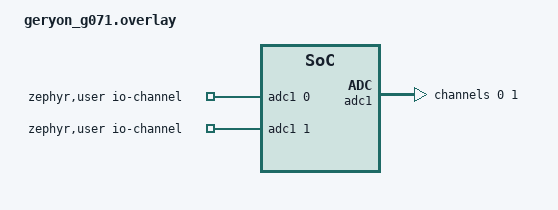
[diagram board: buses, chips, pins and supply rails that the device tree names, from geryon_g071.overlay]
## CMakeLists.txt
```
# SPDX-License-Identifier: Apache-2.0

cmake_minimum_required(VERSION 3.20.0)
set(BOARD_ROOT ${CMAKE_CURRENT_LIST_DIR})
find_package(Zephyr REQUIRED HINTS $ENV{ZEPHYR_BASE})

if(DEFINED ENV{VERSION})
project(app LANGUAGES C VERSION $ENV{VERSION})
else()
project(app LANGUAGES C VERSION 0.1.0)
endif()

set(PROJECT_VERSION_RC 7)

if(PROJECT_VERSION_RC)
  set(PROJECT_VERSION_SUFFIX "rc${PROJECT_VERSION_RC}")
else()
  set(PROJECT_VERSION_SUFFIX "")
endif()

if(PROJECT_VERSION_SUFFIX)
  set(PROJECT_VERSION ${PROJECT_VERSION}-${PROJECT_VERSION_SUFFIX})
endif()


configure_file(app_version.h.in ${CMAKE_BINARY_DIR}/app/include/app_version.h)

target_sources(app PRIVATE 
  src/main.c
  src/pwm.c  
  src/protocol.c
  src/io.c
  src/app_event_manager.c
  src/cset.c
  src/cmon.c
  src/mcp466.c
  src/pwm_gpio.c
  src/common.c
)
```

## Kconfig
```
menu "Geryon Application"

config SUPPORT_HAL_STM32
	bool "Enable HAL API for STM32"
	default y
	select USE_STM32_HAL_TIM
	select USE_STM32_HAL_TIM_EX
	select USE_STM32_HAL_GPIO
endmenu

menu "Zephyr Kernel"
source "$ZEPHYR_BASE/Kconfig.zephyr"
endmenu

module = GERYON_APP
module-str = Geryon App
source "${ZEPHYR_BASE}/subsys/logging/Kconfig.template.log_config"
```

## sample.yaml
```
sample:
  name: Geryon Lazer Application
```

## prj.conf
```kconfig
CONFIG_LOG=y
CONFIG_SHELL=y
# Config Random
CONFIG_ENTROPY_GENERATOR=y
CONFIG_TEST_RANDOM_GENERATOR=y

CONFIG_DAC=y
CONFIG_ADC=y
CONFIG_I2C=y
CONFIG_GPIO=y
CONFIG_GPIO_SHELL=y
CONFIG_LOG_DEFAULT_LEVEL=1
```

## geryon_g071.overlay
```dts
#include <zephyr/dt-bindings/adc/adc.h>

 / {
	zephyr,user {
		// io-channels = <&adc1 0>, <&adc1 1>, <&adc1 2>;
        io-channels = <&adc1 0>, <&adc1 1>;
	};
};

&adc1 {
    status = "okay";
	#address-cells = <1>;
	#size-cells = <0>;

	channel@0 {
		reg = <0>;
		zephyr,gain = "ADC_GAIN_1";
		zephyr,reference = "ADC_REF_INTERNAL";
		zephyr,acquisition-time = <ADC_ACQ_TIME_DEFAULT>;
		zephyr,resolution = <12>;
	};

    channel@1 {
		reg = <1>;
		zephyr,gain = "ADC_GAIN_1";
		zephyr,reference = "ADC_REF_INTERNAL";
		zephyr,acquisition-time = <ADC_ACQ_TIME_DEFAULT>;
		zephyr,resolution = <12>;
	};

    // channel@2 {
	// 	reg = <2>;
	// 	zephyr,gain = "ADC_GAIN_1";
	// 	zephyr,reference = "ADC_REF_INTERNAL";
	// 	zephyr,acquisition-time = <ADC_ACQ_TIME_DEFAULT>;
	// 	zephyr,resolution = <12>;
	// };
};
```

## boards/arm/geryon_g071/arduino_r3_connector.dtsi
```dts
/*
 * Copyright (c) 2019 Linaro Limited
 *
 * SPDX-License-Identifier: Apache-2.0
 */

 / {
	arduino_header: connector {
		compatible = "arduino-header-r3";
		#gpio-cells = <2>;
		gpio-map-mask = <0xffffffff 0xffffffc0>;
		gpio-map-pass-thru = <0 0x3f>;
		gpio-map = <0 0 &gpioa 0 0>,	/* A0 */
			   <1 0 &gpioa 1 0>,	/* A1 */
			   <2 0 &gpioa 4 0>,	/* A2 */
			   <3 0 &gpiob 1 0>,	/* A3 */
			   <4 0 &gpiob 11 0>,	/* A4 */
			   <5 0 &gpiob 12 0>,	/* A5 */
			   <6 0 &gpioc 5 0>,	/* D0 */
			   <7 0 &gpioc 4 0>,	/* D1 */
			   <8 0 &gpioa 10 0>,	/* D2 */
			   <9 0 &gpiob 3 0>,	/* D3 */
			   <10 0 &gpiob 5 0>,	/* D4 */
			   <11 0 &gpiob 4 0>,	/* D5 */
			   <12 0 &gpiob 14 0>,	/* D6 */
			   <13 0 &gpioa 8 0>,	/* D7 */
			   <14 0 &gpioa 9 0>,	/* D8 */
			   <15 0 &gpioc 7 0>,	/* D9 */
			   <16 0 &gpiob 0 0>,	/* D10 */
			   <17 0 &gpioa 7 0>,	/* D11 */
			   <18 0 &gpioa 6 0>,	/* D12 */
			   <19 0 &gpioa 5 0>,	/* D13 */
			   <20 0 &gpiob 9 0>,	/* D14 */
			   <21 0 &gpiob 8 0>;	/* D15 */
	};
};

arduino_i2c: &i2c1 {};
arduino_spi: &spi1 {};
arduino_serial: &usart1 {};
```

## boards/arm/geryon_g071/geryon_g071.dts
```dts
/*
 * Copyright (c) 2023 Marin Jurjević <marin.jurjevic@hotmail.com>
 *
 * SPDX-License-Identifier: Apache-2.0
 */

/dts-v1/;
#include <st/g0/stm32g071Xb.dtsi>
#include <st/g0/stm32g071r(6-8-b)tx-pinctrl.dtsi>
#include "arduino_r3_connector.dtsi"

/ {
	model = "STMicroelectronics STM32G071RB-NUCLEO board";
	compatible = "st,stm32g071rb-nucleo";

	chosen {
		zephyr,console = &usart1;
		zephyr,shell-uart = &usart1;
		zephyr,sram = &sram0;
		zephyr,flash = &flash0;
	};

	power-states {
		stop0: state0 {
			compatible = "zephyr,power-state";
			power-state-name = "suspend-to-idle";
			substate-id = <1>;
			min-residency-us = <20>;
		};
		stop1: state1 {
			compatible = "zephyr,power-state";
			power-state-name = "suspend-to-idle";
			substate-id = <2>;
			min-residency-us = <100>;
		};
	};

	board-control {
		global_en: global-en {
			compatible = "alma,input";
			control-gpios = <&gpioc 13 GPIO_ACTIVE_HIGH>;
			status = "okay";
		};
		status_out: status-out {
			compatible = "alma,output";
			control-gpios = <&gpioc 14 GPIO_ACTIVE_LOW>;
			status = "okay";
		};
		reset_int: reset-int {
			compatible = "alma,input";
			control-gpios = <&gpioc 15 GPIO_ACTIVE_HIGH>;
			status = "okay";
		};
		fan_out: fan-out {
			compatible = "alma,output";
			control-gpios = <&gpiof 0 GPIO_ACTIVE_HIGH>;
			status = "okay";
		};
		ot_int: ot-int {
			compatible = "alma,input";
			control-gpios = <&gpiof 1 GPIO_ACTIVE_HIGH>;
			status = "okay";
		};
		oc2_int: oc2-int {
			compatible = "alma,input";
			control-gpios = <&gpioa 6 GPIO_ACTIVE_HIGH>;
			status = "okay";
		};
		ov2_int: ov2-int {
			compatible = "alma,input";
			control-gpios = <&gpioa 7 GPIO_ACTIVE_HIGH>;
			status = "okay";
		};
		pulse2_out: pulse2-out {
			compatible = "alma,output";
			control-gpios = <&gpiob 1 GPIO_ACTIVE_HIGH>;
			status = "okay";
		};
		pwm2_out: pwm2-out {
			compatible = "alma,output";
			control-gpios = <&gpiob 2 GPIO_ACTIVE_HIGH>;
			status = "okay";
		};
		state2_out: state2-out {
			compatible = "alma,output";
			control-gpios = <&gpiob 11 GPIO_ACTIVE_HIGH>;
			status = "okay";
		};
		state3_out: state3-out {
			compatible = "alma,output";
			control-gpios = <&gpiob 12 GPIO_ACTIVE_HIGH>;
			status = "okay";
		};
		drv_en2_out: drv-en2-out {
			compatible = "alma,output";
			control-gpios = <&gpiob 15 GPIO_ACTIVE_HIGH>;
			status = "okay";
		};
		drv_en1_out: drv-en1-out {
			compatible = "alma,output";
			control-gpios = <&gpioa 8 GPIO_ACTIVE_HIGH>;
			status = "okay";
		};
		rs232_shdn_out: rs232-shdn-out {
			compatible = "alma,output";
			control-gpios = <&gpioc 6 GPIO_ACTIVE_HIGH>;
			status = "okay";
		};
		rs232_en_out: rs232-en-out {
			compatible = "alma,output";
			control-gpios = <&gpioc 7 GPIO_ACTIVE_HIGH>;
			status = "okay";
		};
		reset_n_out: reset-n-out {
			compatible = "alma,output";
			control-gpios = <&gpioa 11 GPIO_ACTIVE_HIGH>;
			status = "okay";
		};
		state1_out: state1-out {
			compatible = "alma,output";
			control-gpios = <&gpiod 0 GPIO_ACTIVE_HIGH>;
			status = "okay";
		};
		flt_int: flt-int {
			compatible = "alma,input";
			control-gpios = <&gpiob 8 GPIO_ACTIVE_HIGH>;
			status = "okay";
		};
		pulse1_out: pulse1-out {
			compatible = "alma,output";
			control-gpios = <&gpiod 3 GPIO_ACTIVE_HIGH>;
			status = "okay";
		};
		pwm1_out: pwm1-out {
			compatible = "alma,output";
			control-gpios = <&gpiod 2 GPIO_ACTIVE_HIGH>;
			status = "okay";
		};
		oc1_int: oc1-int {
			compatible = "alma,input";
			control-gpios = <&gpiob 5 GPIO_ACTIVE_HIGH>;
			status = "okay";
		};
		ov1_int: ov1-int {
			compatible = "alma,input";
			control-gpios = <&gpiob 4 GPIO_ACTIVE_HIGH>;
			status = "okay";
		};
	};

	aliases {
		alma-uart = &usart2;
		watchdog0 = &iwdg;
	};
};

&clk_lsi {
	status = "okay";
};

&clk_hsi {
	status = "okay";
};

&pll {
	div-m = <2>;
	mul-n = <25>;
	div-p = <2>;
	div-q = <2>;
	div-r = <4>;
	clocks = <&clk_hsi>;
	status = "okay";
};

&rcc {
	clocks = <&pll>;
	clock-frequency = <DT_FREQ_M(50)>;
	ahb-prescaler = <1>;
	apb1-prescaler = <1>;
};

&usart1 {
	pinctrl-0 = <&usart1_tx_pa9 &usart1_rx_pa10>;
	pinctrl-names = "default";
	current-speed = <115200>;
	status = "okay";
};

&usart2 {
	pinctrl-0 = <&usart2_tx_pa2 &usart2_rx_pa3>;
	pinctrl-names = "default";
	current-speed = <38400>;
	status = "okay";
};

&rtc {
	clocks = <&rcc STM32_CLOCK_BUS_APB1 0x00000400>,
	         <&rcc STM32_SRC_LSI RTC_SEL(2)>;
	status = "okay";
};

&iwdg {
	status = "okay";
};

&i2c1 {
	pinctrl-0 = <&i2c1_scl_pb6 &i2c1_sda_pb7>;
	pinctrl-names = "default";
	status = "okay";
	clock-frequency = <I2C_BITRATE_FAST>;
};

&adc1 {
	pinctrl-0 = <&adc1_in0_pa0 &adc1_in1_pa1>;
	pinctrl-names = "default";
	status = "okay";
	vref-mv = <3300>;
};

&dac1 {
	status = "okay";
	pinctrl-0 = <&dac1_out1_pa4 &dac1_out2_pa5>;
	pinctrl-names = "default";
};

&die_temp {
	status = "okay";
};

&flash0 {
	partitions {
		compatible = "fixed-partitions";
		#address-cells = <1>;
		#size-cells = <1>;

		/* Set 2KB of storage at the end of 128KB flash */
		storage_partition: partition@1f800 {
			label = "storage";
			reg = <0x0001f800 DT_SIZE_K(2)>;
		};
	};
};

&cpu0 {
	cpu-power-states = <&stop0 &stop1>;
};

&lptim1 {
	clocks = <&rcc STM32_CLOCK_BUS_APB1 0x80000000>,
	         <&rcc STM32_SRC_LSI LPTIM1_SEL(1)>;
	status = "okay";
};
```

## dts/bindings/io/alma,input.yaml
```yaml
description: Input IO

compatible: "alma,input"

include: base.yaml

properties:
    status:
      required: true

    control-gpios:
      type: phandle-array
      required: true
      description: |
        GPIO input
```

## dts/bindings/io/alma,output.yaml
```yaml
description: Alma Output IO

compatible: "alma,output"

include: base.yaml

properties:
    status:
      required: true

    control-gpios:
      type: phandle-array
      required: true
      description: |
        GPIO output
```

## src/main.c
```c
#include <zephyr/device.h>
#include <zephyr/kernel.h>
#include <zephyr/logging/log.h>
#include <zephyr/sys/printk.h>

LOG_MODULE_REGISTER(geryon_main, LOG_LEVEL_ERR);

#include "app_event_manager.h"
#include "cmon.h"
#include "cset.h"
#include "io.h"
#include "main.h"
#include "mcp466.h"
#include "protocol.h"
#include "pwm.h"
#include "pwm_gpio.h"

struct alma_data global_alma_data = {.sync_freq = 250000,
                                     .jitter = 1,
                                     .pulse_freq = 10,
                                     .pulse_dc = {10, 10},
                                     .op_mode = 1,
                                     .pulse_mode = 0};

#define MAX_NUM_GPIO_PINS 4

uint8_t pin_gpios[MAX_NUM_GPIO_PINS];
uint8_t freqs[MAX_NUM_GPIO_PINS];
uint8_t duty_cycles[MAX_NUM_GPIO_PINS];
uint8_t num_pins = 0;

void main_init_flow(void) {
  io_set(IO_STATUS_OUT, 0);
  io_set(IO_PULSE1_OUT, 1);
  io_set(IO_PULSE2_OUT, 0);
  io_set(IO_DRV_EN1_OUT, 1);
  io_set(IO_DRV_EN2_OUT, 0);
  io_set(IO_PWM1_OUT, 0);
  io_set(IO_PWM2_OUT, 0);
  cset_out(CSET_CH_1, 0);
  cset_out(CSET_CH_2, 0);
  mcp466_write(MCP466_CH_1, 0, 0);
  mcp466_write(MCP466_CH_2, 0, 0);
  mcp466_write(MCP466_CH_1, 1, 0);
  mcp466_write(MCP466_CH_2, 1, 0);
  io_set(IO_RS232_SHDN_OUT, 1);
  io_set(IO_RS232_EN_OUT, 0);
  io_set(IO_RESET_N_OUT, 1);
  io_set(IO_STATE1_OUT, 1);
  io_set(IO_STATE2_OUT, 0);
  io_set(IO_STATE3_OUT, 0);
}

void main_close_laser_flow(void) {
  pin_gpios[0] = IO_PWM1_OUT;
  pin_gpios[1] = IO_PWM2_OUT;
  pin_gpios[2] = CSET_CH_1;
  pin_gpios[3] = CSET_CH_2;
  num_pins = 4;
  stop_pwm_pins(pin_gpios, num_pins);
  io_set(IO_PWM1_OUT, 0);
  io_set(IO_PWM2_OUT, 0);
  cset_out(CSET_CH_1, 0);
  cset_out(CSET_CH_2, 0);
  io_set(IO_PULSE1_OUT, 0);
  io_set(IO_PULSE2_OUT, 0);
  io_set(IO_DRV_EN1_OUT, 0);
  io_set(IO_DRV_EN2_OUT, 0);
  io_set(IO_STATUS_OUT, 1);
}

void main_opmode_1_flow(void) {
  io_set(IO_PULSE1_OUT, 1);
  io_set(IO_PULSE2_OUT, 0);
  io_set(IO_DRV_EN1_OUT, 1);
  io_set(IO_DRV_EN2_OUT, 0);
  freqs[0] = global_alma_data.pulse_freq;
  duty_cycles[0] = global_alma_data.pulse_dc[0];
  num_pins = 1;
  if (global_alma_data.pulse_mode == 1) {
    io_set(IO_PWM1_OUT, 1);
    pin_gpios[0] = SIGNAL_CSET_1;
  } else if (global_alma_data.pulse_mode == 0) {
    cset_out(CSET_CH_1, 128);
    pin_gpios[0] = SIGNAL_PWM_1;
  }

  stop_pwm_pins(pin_gpios, num_pins);
  start_pwm_pins(pin_gpios, freqs, duty_cycles, num_pins, -1);
  io_set(IO_STATE1_OUT, 0);
  io_set(IO_STATE2_OUT, 0);
  io_set(IO_STATE3_OUT, 0);
}

void main_opmode_2_flow(void) {
  io_set(IO_PULSE1_OUT, 0);
  io_set(IO_PULSE2_OUT, 1);
  io_set(IO_DRV_EN1_OUT, 0);
  io_set(IO_DRV_EN2_OUT, 1);
  freqs[0] = global_alma_data.pulse_freq;
  duty_cycles[0] = global_alma_data.pulse_dc[1];
  num_pins = 1;
  if (global_alma_data.pulse_mode == 1) {
    io_set(IO_PWM2_OUT, 1);
    pin_gpios[0] = SIGNAL_CSET_2;
  } else if (global_alma_data.pulse_mode == 0) {
    cset_out(CSET_CH_2, 128);
    pin_gpios[0] = SIGNAL_PWM_2;
  }

  stop_pwm_pins(pin_gpios, num_pins);
  start_pwm_pins(pin_gpios, freqs, duty_cycles, num_pins, -1);
  io_set(IO_STATE1_OUT, 0);
  io_set(IO_STATE2_OUT, 0);
  io_set(IO_STATE3_OUT, 0);
}

void main_opmode_3_flow(void) {
  io_set(IO_PULSE1_OUT, 1);
  io_set(IO_PULSE2_OUT, 1);
  io_set(IO_DRV_EN1_OUT, 1);
  io_set(IO_DRV_EN2_OUT, 1);
  freqs[0] = global_alma_data.pulse_freq;
  freqs[1] = global_alma_data.pulse_freq;
  duty_cycles[0] = global_alma_data.pulse_dc[0];
  duty_cycles[1] = global_alma_data.pulse_dc[1];
  num_pins = 2;
  if (global_alma_data.pulse_mode == 1) {
    pin_gpios[0] = SIGNAL_CSET_1;
    pin_gpios[1] = SIGNAL_CSET_2;
    io_set(IO_PWM1_OUT, 1);
    io_set(IO_PWM2_OUT, 1);
  } else if (global_alma_data.pulse_mode == 0) {
    cset_out(CSET_CH_1, 128);
    cset_out(CSET_CH_2, 128);
    pin_gpios[0] = SIGNAL_PWM_1;
    pin_gpios[1] = SIGNAL_PWM_2;
  }

  stop_pwm_pins(pin_gpios, num_pins);
  start_pwm_pins(pin_gpios, freqs, duty_cycles, num_pins, -1);
  io_set(IO_STATE1_OUT, 0);
  io_set(IO_STATE2_OUT, 0);
  io_set(IO_STATE3_OUT, 1);
}

void main_opmode_4_flow(void) {
  io_set(IO_PULSE1_OUT, 1);
  io_set(IO_PULSE2_OUT, 1);
  io_set(IO_DRV_EN1_OUT, 1);
  io_set(IO_DRV_EN2_OUT, 1);
  freqs[0] = global_alma_data.pulse_freq;
  freqs[1] = global_alma_data.pulse_freq;
  duty_cycles[0] = global_alma_data.pulse_dc[0];
  duty_cycles[1] = global_alma_data.pulse_dc[1];
  if (global_alma_data.pulse_mode == 1) {
    pin_gpios[0] = SIGNAL_CSET_1;
    pin_gpios[1] = SIGNAL_CSET_2;
    io_set(IO_PWM1_OUT, 1);
    io_set(IO_PWM2_OUT, 1);
  } else if (global_alma_data.pulse_mode == 0) {
    cset_out(CSET_CH_1, 128);
    cset_out(CSET_CH_2, 128);
    pin_gpios[0] = SIGNAL_PWM_1;
    pin_gpios[1] = SIGNAL_PWM_2;
  }
  num_pins = 2;
  stop_pwm_pins(pin_gpios, num_pins);
  start_pwm_pins(pin_gpios, freqs, duty_cycles, num_pins, 1);
  io_set(IO_STATE1_OUT, 1);
  io_set(IO_STATE2_OUT, 1);
  io_set(IO_STATE3_OUT, 0);
}

void main(void) {
  io_init();
  io_interrupt_disable();
  cset_init();
  cmon_init();
  pwm_init();
  pwm_pins_init();
  mcp466_init();
  main_init_flow();
  protocol_init();
  while (1) {
    struct app_event evt;
    /* Wait for the next event */
    int err = app_event_manager_get(&evt);
    if (err) {
      LOG_WRN("Unable to get event. Err: %i", err);
      continue;
    }

    switch (evt.type) {
    case APP_EVENT_IN_GLOBAL_EN_RISING: {
      LOG_DBG("APP_EVENT_IN_GLOBAL_EN_RISING");
      /* Start pulse flow */
      pwm_start();
      io_set(IO_RS232_EN_OUT, 1); // Disable RS232
      if (global_alma_data.op_mode == 1)
        main_opmode_1_flow();
      else if (global_alma_data.op_mode == 2)
        main_opmode_2_flow();
      else if (global_alma_data.op_mode == 3)
        main_opmode_3_flow();
      else if (global_alma_data.op_mode == 4)
        main_opmode_4_flow();
      break;
    }
    case APP_EVENT_IN_GLOBAL_EN_FALLING: {
      LOG_DBG("APP_EVENT_IN_GLOBAL_EN_FALLING");
      /* Stop pusle flow */
      pwm_stop();
      num_pins = 4;
      pin_gpios[0] = SIGNAL_CSET_1;
      pin_gpios[1] = SIGNAL_CSET_2;
      pin_gpios[2] = SIGNAL_PWM_1;
      pin_gpios[3] = SIGNAL_PWM_2;
      stop_pwm_pins(pin_gpios, num_pins);
      io_set(IO_RS232_EN_OUT, 0); // Enable RS232
      break;
    }
    case APP_EVENT_IN_RESET: {
      LOG_DBG("APP_EVENT_IN_RESET");
      io_set(IO_RESET_N_OUT, 1);
      if (global_alma_data.op_mode == 1) {
        io_set(IO_PULSE1_OUT, 1);
        io_set(IO_PULSE2_OUT, 0);
        io_set(IO_DRV_EN1_OUT, 1);
        io_set(IO_DRV_EN2_OUT, 0);
        io_set(IO_STATE1_OUT, 0);
        io_set(IO_STATE2_OUT, 0);
      } else if (global_alma_data.op_mode == 2) {
        io_set(IO_PULSE1_OUT, 0);
        io_set(IO_PULSE2_OUT, 1);
        io_set(IO_DRV_EN1_OUT, 0);
        io_set(IO_DRV_EN2_OUT, 1);
        io_set(IO_STATE1_OUT, 0);
        io_set(IO_STATE2_OUT, 0);
      } else if (global_alma_data.op_mode == 3) {
        io_set(IO_PULSE1_OUT, 1);
        io_set(IO_PULSE2_OUT, 1);
        io_set(IO_DRV_EN1_OUT, 1);
        io_set(IO_DRV_EN2_OUT, 1);
        io_set(IO_STATE1_OUT, 0);
        io_set(IO_STATE2_OUT, 0);
        io_set(IO_STATE2_OUT, 1);
      } else if (global_alma_data.op_mode == 4) {
        io_set(IO_PULSE1_OUT, 1);
        io_set(IO_PULSE2_OUT, 1);
        io_set(IO_DRV_EN1_OUT, 1);
        io_set(IO_DRV_EN2_OUT, 1);
        io_set(IO_STATE1_OUT, 1);
        io_set(IO_STATE2_OUT, 1);
        io_set(IO_STATE2_OUT, 0);
      }
      break;
    }
    case APP_EVENT_IN_OT:
      LOG_DBG("APP_EVENT_IN_OT");
      main_close_laser_flow();
      protop_send_error_message(OT_ERR);
      break;
    case APP_EVENT_IN_OC2:
    LOG_DBG("APP_EVENT_IN_OC2");
      main_close_laser_flow();
      protop_send_error_message(OC2_ERR);
      break;
    case APP_EVENT_IN_OV2:
    LOG_DBG("APP_EVENT_IN_OV2");
      main_close_laser_flow();
      protop_send_error_message(OV2_ERR);
      break;
    case APP_EVENT_IN_FLT:
    LOG_DBG("APP_EVENT_IN_FLT");
      main_close_laser_flow();
      protop_send_error_message(FLT_ERR);
      break;
    case APP_EVENT_IN_OV1:
    LOG_DBG("APP_EVENT_IN_OV1");
      main_close_laser_flow();
      protop_send_error_message(OV1_ERR);
      break;
    case APP_EVENT_IN_OC1:
    LOG_DBG("APP_EVENT_IN_OC1");
      main_close_laser_flow();
      protop_send_error_message(OC1_ERR);
      break;
    default:
      break;
    }
  }
}
```

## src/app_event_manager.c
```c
#include <zephyr/kernel.h>
#include "app_event_manager.h"
#include <zephyr/logging/log.h>
LOG_MODULE_REGISTER(app_event_manager);

/* Define message queue */
K_MSGQ_DEFINE(app_event_msq, sizeof(struct app_event), APP_EVENT_QUEUE_SIZE, 4);

int app_event_manager_push(struct app_event *p_evt)
{
	return k_msgq_put(&app_event_msq, p_evt, K_NO_WAIT);
}

int app_event_manager_get(const struct app_event *p_evt)
{
	return k_msgq_get(&app_event_msq, (struct app_event *)p_evt, K_FOREVER);
}

char *app_event_type_to_string(enum app_event_type type)
{
	switch (type) {
		case APP_EVENT_IN_GLOBAL_EN_RISING:
			return "APP_EVENT_IN_GLOBAL_EN_RISING";
		case APP_EVENT_IN_GLOBAL_EN_FALLING:
			return "APP_EVENT_IN_GLOBAL_EN_FALLING";
		case APP_EVENT_IN_RESET:
			return "APP_EVENT_IN_RESET";
		case APP_EVENT_IN_OT:
			return "APP_EVENT_IN_OT";
		case APP_EVENT_IN_OC2:
			return "APP_EVENT_IN_OC2";
		case APP_EVENT_IN_OV2:
			return "APP_EVENT_IN_OV2";
		case APP_EVENT_IN_FLT:
			return "APP_EVENT_IN_FLT";
		case APP_EVENT_IN_OV1:
			return "APP_EVENT_IN_OV1";
		case APP_EVENT_IN_OC1:
			return "APP_EVENT_IN_OC1";
		default:
			return "UNKNOWN";
	}
}
```

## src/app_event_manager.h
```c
#ifndef _APP_EVENT_MANAGER_H
#define _APP_EVENT_MANAGER_H

/**
 * @brief Max size of event queue
 * 
 */
#define APP_EVENT_QUEUE_SIZE 24

/**
 * @brief Simplified macro for pushing an app event without data
 * 
 */
#define APP_EVENT_MANAGER_PUSH(x)                                                                  \
	struct app_event app_event_##x = {                                                         \
		.type = x,                                                                         \
	};                                                                                         \
	app_event_manager_push(&app_event_##x);

/**
 * @brief Used to interact with different functionality
 * in this application
 */
enum app_event_type {
	APP_EVENT_IN_GLOBAL_EN_RISING,
	APP_EVENT_IN_GLOBAL_EN_FALLING,
	APP_EVENT_IN_RESET,
	APP_EVENT_IN_OT,
	APP_EVENT_IN_OC2,
	APP_EVENT_IN_OV2,
	APP_EVENT_IN_FLT,
	APP_EVENT_IN_OV1,
	APP_EVENT_IN_OC1,
};

/**
 * @brief Application event that can be passed back to the main
 * context
 * 
 */
struct app_event {
	enum app_event_type type;
	union {
		int err;
	};
};

/**
 * @brief Get the string representation of the Application event
 * 
 * @param type app event type enum
 * @return char* NULL if error
 */
char *app_event_type_to_string(enum app_event_type type);

/**
 * @brief Pushes event to message queue
 * 
 * @param p_evt the event to be copied.
 * @return int 
 */
int app_event_manager_push(struct app_event *p_evt);

/**
 * @brief Gets an event from the message queue
 * 
 * @param p_evt pointer where the data will be copied to.
 * @return int 
 */
int app_event_manager_get(const struct app_event *p_evt);

#endif
```

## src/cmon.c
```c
#include <zephyr/kernel.h>
#include <zephyr/drivers/adc.h>
#include <zephyr/device.h>
#include <zephyr/devicetree.h>
#include <zephyr/kernel.h>
#include <zephyr/sys/printk.h>
#include <zephyr/sys/util.h>

#include <zephyr/logging/log.h>
LOG_MODULE_REGISTER(adc_alma, LOG_LEVEL_ERR);

#if !DT_NODE_EXISTS(DT_PATH(zephyr_user)) || \
	!DT_NODE_HAS_PROP(DT_PATH(zephyr_user), io_channels)
#error "No suitable devicetree overlay specified"
#endif

#define DT_SPEC_AND_COMMA(node_id, prop, idx) \
	ADC_DT_SPEC_GET_BY_IDX(node_id, idx),

/* Data of ADC io-channels specified in devicetree. */
static const struct adc_dt_spec adc_channels[] = {
	DT_FOREACH_PROP_ELEM(DT_PATH(zephyr_user), io_channels,
			     DT_SPEC_AND_COMMA)
};

static int16_t adc_buf;
struct adc_sequence sequence = {
	.buffer = &adc_buf,
	/* buffer size in bytes, not number of samples */
	.buffer_size = sizeof(adc_buf),
};


void cmon_init(void) {

	/* Configure channels individually prior to sampling. */
	for (size_t i = 0U; i < ARRAY_SIZE(adc_channels); i++) {
		if (!device_is_ready(adc_channels[i].dev)) {
			LOG_ERR("ADC controller device not ready");
			return;
		}

		int err = adc_channel_setup_dt(&adc_channels[i]);
		if (err < 0) {
			LOG_ERR("Could not setup channel #%d (%d)", i, err);
			return;
		}
	}

    LOG_INF("Setup ADC for CMON successfully");
}

int cmon_get(int channel) {
	int32_t val_mv;
	(void)adc_sequence_init_dt(&adc_channels[channel], &sequence);

	int err = adc_read(adc_channels[channel].dev, &sequence);
	if (err < 0) {
		LOG_ERR("Could not read (%d)", err);
        return 0;
	} else {
		LOG_DBG("Raw buf: %d", adc_buf);
	}

	/* conversion to mV may not be supported, skip if not */
	val_mv = adc_buf;
	err = adc_raw_to_millivolts_dt(&adc_channels[channel],
				       &val_mv);
	if (err < 0) {
		LOG_DBG(" (value in mV not available)");
	} else {
		LOG_INF(" Voltage: %d mV", val_mv);
	}

    return val_mv;
}
```

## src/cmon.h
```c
#ifndef CMON_H_
#define CMON_H_

#include <stdint.h>

enum {
    CMON_CH_1 = 0, 
    CMON_CH_2 = 1,
    E_SENSE = 2,
};

void cmon_init(void);
int cmon_get(int channel);

#endif /* CMON_H_ */
```

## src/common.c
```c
int custom_atoi(const char *str) {
    int result = 0;
    int sign = 1;
    int i = 0;

    while (str[i] == ' ' || str[i] == '\t')
        i++;

    if (str[i] == '-') {
        sign = -1;
        i++;
    } else if (str[i] == '+') {
        i++;
    }

    while (str[i] >= '0' && str[i] <= '9') {
        result = result * 10 + (str[i] - '0');
        i++;
    }

    return result * sign;
}
```

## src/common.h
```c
#ifndef MYCOMMON_H_
#define MYCOMMON_H_

int custom_atoi(const char *str);

#endif /* MYCOMMON_H_ */
```

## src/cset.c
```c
#include <zephyr/kernel.h>
#include <zephyr/drivers/dac.h>

#include <zephyr/logging/log.h>
LOG_MODULE_REGISTER(dac_alma, LOG_LEVEL_ERR);

#include "cset.h"

static const struct device *const dac_dev = DEVICE_DT_GET(DT_NODELABEL(dac1));

static int last_ch_value[2] = {0, 0};

static const struct dac_channel_cfg dac_ch_cfg[2] = {
    {
        .channel_id = 1,
        .resolution = 12,
    },
    {
        .channel_id = 2,
        .resolution = 12
    }
};

void cset_init(void) {
	if (!device_is_ready(dac_dev)) {
		LOG_ERR("DAC device %s is not ready", dac_dev->name);
		return;
	}

	for (int i = 0; i < CSET_NUM; i++) {
		int ret = dac_channel_setup(dac_dev, &dac_ch_cfg[i]);

		if (ret != 0) {
			LOG_ERR("Setting up of DAC channel failed with code %d", ret);
			return;
		}
	}

    LOG_INF("Setup DAC for CSET successfully");
}

void cset_out(int channel, int value) {
	if (!device_is_ready(dac_dev)) {
		LOG_ERR("DAC device %s is not ready", dac_dev->name);
		return;
	}

    last_ch_value[channel] = value;
	
    dac_write_value(dac_dev, dac_ch_cfg[channel].channel_id, value);
}

int  cset_get_last_value(int channel) {
    return last_ch_value[channel];
}
```

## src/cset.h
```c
#ifndef CSET_H_
#define CSET_H_

#include <stdint.h>

enum {
    CSET_CH_1,
    CSET_CH_2,
    CSET_NUM
};

void cset_init(void);
int  cset_get_last_value(int channel);
void cset_out(int channel, int value);

#endif /* CSET_H_ */
```

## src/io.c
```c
#include <zephyr/kernel.h>
#include <zephyr/drivers/gpio.h>
#include <zephyr/device.h>
#include <zephyr/sys/slist.h>
#include <zephyr/logging/log.h>
LOG_MODULE_REGISTER(io, LOG_LEVEL_ERR);

#include "io.h"
#include "app_event_manager.h"

static const struct gpio_dt_spec global_en_dt = GPIO_DT_SPEC_GET_OR(DT_NODELABEL(global_en), control_gpios, 0);
static const struct gpio_dt_spec status_out_dt = GPIO_DT_SPEC_GET_OR(DT_NODELABEL(status_out), control_gpios, 0);
static const struct gpio_dt_spec reset_int_dt = GPIO_DT_SPEC_GET_OR(DT_NODELABEL(reset_int), control_gpios, 0);
static const struct gpio_dt_spec fan_out_dt = GPIO_DT_SPEC_GET_OR(DT_NODELABEL(fan_out), control_gpios, 0);
static const struct gpio_dt_spec ot_int_dt = GPIO_DT_SPEC_GET_OR(DT_NODELABEL(ot_int), control_gpios, 0);
static const struct gpio_dt_spec oc2_int_dt = GPIO_DT_SPEC_GET_OR(DT_NODELABEL(oc2_int), control_gpios, 0);
static const struct gpio_dt_spec ov2_int_dt = GPIO_DT_SPEC_GET_OR(DT_NODELABEL(ov2_int), control_gpios, 0);
static const struct gpio_dt_spec pulse2_out_dt = GPIO_DT_SPEC_GET_OR(DT_NODELABEL(pulse2_out), control_gpios, 0);
static const struct gpio_dt_spec pwm2_out_dt = GPIO_DT_SPEC_GET_OR(DT_NODELABEL(pwm2_out), control_gpios, 0);
static const struct gpio_dt_spec state2_out_dt = GPIO_DT_SPEC_GET_OR(DT_NODELABEL(state2_out), control_gpios, 0);
static const struct gpio_dt_spec state3_out_dt = GPIO_DT_SPEC_GET_OR(DT_NODELABEL(state3_out), control_gpios, 0);
static const struct gpio_dt_spec drv_en2_out_dt = GPIO_DT_SPEC_GET_OR(DT_NODELABEL(drv_en2_out), control_gpios, 0);
static const struct gpio_dt_spec drv_en1_out_dt = GPIO_DT_SPEC_GET_OR(DT_NODELABEL(drv_en1_out), control_gpios, 0);
static const struct gpio_dt_spec rs232_shdn_out_dt = GPIO_DT_SPEC_GET_OR(DT_NODELABEL(rs232_shdn_out), control_gpios, 0);
static const struct gpio_dt_spec rs232_en_out_dt = GPIO_DT_SPEC_GET_OR(DT_NODELABEL(rs232_en_out), control_gpios, 0);
static const struct gpio_dt_spec reset_n_out_dt = GPIO_DT_SPEC_GET_OR(DT_NODELABEL(reset_n_out), control_gpios, 0);
static const struct gpio_dt_spec state1_out_dt = GPIO_DT_SPEC_GET_OR(DT_NODELABEL(state1_out), control_gpios, 0);
static const struct gpio_dt_spec flt_int_dt = GPIO_DT_SPEC_GET_OR(DT_NODELABEL(flt_int), control_gpios, 0);
static const struct gpio_dt_spec pulse1_out_dt = GPIO_DT_SPEC_GET_OR(DT_NODELABEL(pulse1_out), control_gpios, 0);
static const struct gpio_dt_spec pwm1_out_dt = GPIO_DT_SPEC_GET_OR(DT_NODELABEL(pwm1_out), control_gpios, 0);
static const struct gpio_dt_spec oc1_int_dt = GPIO_DT_SPEC_GET_OR(DT_NODELABEL(oc1_int), control_gpios, 0);
static const struct gpio_dt_spec ov1_int_dt = GPIO_DT_SPEC_GET_OR(DT_NODELABEL(ov1_int), control_gpios, 0);

static struct gpio_callback global_en_cb;
static struct gpio_callback reset_int_cb;
static struct gpio_callback ot_int_cb;
static struct gpio_callback oc2_int_cb;
static struct gpio_callback ov2_int_cb;
static struct gpio_callback flt_int_cb;
static struct gpio_callback oc1_int_cb;
static struct gpio_callback ov1_int_cb;

static void global_en_callback_handler(const struct device *port, struct gpio_callback *cb, gpio_port_pins_t pins) {
	struct app_event event;
	uint8_t level = gpio_pin_get_dt(&global_en_dt);
	LOG_DBG("Level %d", level);
	if (level == 0) {
		event.type = APP_EVENT_IN_GLOBAL_EN_FALLING;
	} else if (level == 1) {
		event.type = APP_EVENT_IN_GLOBAL_EN_RISING;
	} else {
		event.type = APP_EVENT_IN_GLOBAL_EN_FALLING;
	}
	app_event_manager_push(&event);
}

static void reset_int_callback_handler(const struct device *port, struct gpio_callback *cb, gpio_port_pins_t pins) {
	struct app_event event = {
		.type = APP_EVENT_IN_RESET,
	};
    app_event_manager_push(&event);
}

static void ot_int_callback_handler(const struct device *port, struct gpio_callback *cb, gpio_port_pins_t pins) {
	struct app_event event = {
		.type = APP_EVENT_IN_OT,
	};
    app_event_manager_push(&event);
}

static void oc2_int_callback_handler(const struct device *port, struct gpio_callback *cb, gpio_port_pins_t pins) {
	struct app_event event = {
		.type = APP_EVENT_IN_OC2,
	};
    app_event_manager_push(&event);
}

static void ov2_int_callback_handler(const struct device *port, struct gpio_callback *cb, gpio_port_pins_t pins) {
	struct app_event event = {
		.type = APP_EVENT_IN_OV2,
	};
    app_event_manager_push(&event);
}

static void flt_int_callback_handler(const struct device *port, struct gpio_callback *cb, gpio_port_pins_t pins) {
	struct app_event event = {
		.type = APP_EVENT_IN_FLT,
	};
    app_event_manager_push(&event);
}

static void oc1_int_callback_handler(const struct device *port, struct gpio_callback *cb, gpio_port_pins_t pins) {
	struct app_event event = {
		.type = APP_EVENT_IN_OV1,
	};
    app_event_manager_push(&event);
}

static void ov1_int_callback_handler(const struct device *port, struct gpio_callback *cb, gpio_port_pins_t pins) {
	struct app_event event = {
		.type = APP_EVENT_IN_OC1,
	};
    app_event_manager_push(&event);
}

int io_init(void)
{
	if (!device_is_ready(global_en_dt.port)) {
		LOG_ERR("Can't get the device %s", global_en_dt.port->name);
		return -EINVAL;
	}

	if (!device_is_ready(status_out_dt.port)) {
		LOG_ERR("Can't get the device %s", status_out_dt.port->name);
		return -EINVAL;
	}

	if (!device_is_ready(reset_int_dt.port)) {
		LOG_ERR("Can't get the device %s", reset_int_dt.port->name);
		return -EINVAL;
	}
    
	if (!device_is_ready(fan_out_dt.port)) {
		LOG_ERR("Can't get the device %s", fan_out_dt.port->name);
		return -EINVAL;
	}

	if (!device_is_ready(ot_int_dt.port)) {
		LOG_ERR("Can't get the device %s", ot_int_dt.port->name);
		return -EINVAL;
	}

	if (!device_is_ready(oc2_int_dt.port)) {
		LOG_ERR("Can't get the device %s", oc2_int_dt.port->name);
		return -EINVAL;
	}

	if (!device_is_ready(ov2_int_dt.port)) {
		LOG_ERR("Can't get the device %s", ov2_int_dt.port->name);
		return -EINVAL;
	}

	if (!device_is_ready(pulse2_out_dt.port)) {
		LOG_ERR("Can't get the device %s", pulse2_out_dt.port->name);
		return -EINVAL;
	}

	if (!device_is_ready(pwm2_out_dt.port)) {
		LOG_ERR("Can't get the device %s", pwm2_out_dt.port->name);
		return -EINVAL;
	}

	if (!device_is_ready(state2_out_dt.port)) {
		LOG_ERR("Can't get the device %s", state2_out_dt.port->name);
		return -EINVAL;
	}

	if (!device_is_ready(state3_out_dt.port)) {
		LOG_ERR("Can't get the device %s", state3_out_dt.port->name);
		return -EINVAL;
	}

	if (!device_is_ready(drv_en2_out_dt.port)) {
		LOG_ERR("Can't get the device %s", drv_en2_out_dt.port->name);
		return -EINVAL;
	}

	if (!device_is_ready(drv_en1_out_dt.port)) {
		LOG_ERR("Can't get the device %s", drv_en1_out_dt.port->name);
		return -EINVAL;
	}

	if (!device_is_ready(rs232_shdn_out_dt.port)) {
		LOG_ERR("Can't get the device %s", rs232_shdn_out_dt.port->name);
		return -EINVAL;
	}

	if (!device_is_ready(rs232_en_out_dt.port)) {
		LOG_ERR("Can't get the device %s", rs232_en_out_dt.port->name);
		return -EINVAL;
	}

	if (!device_is_ready(reset_n_out_dt.port)) {
		LOG_ERR("Can't get the device %s", reset_n_out_dt.port->name);
		return -EINVAL;
	}

	if (!device_is_ready(state1_out_dt.port)) {
		LOG_ERR("Can't get the device %s", state1_out_dt.port->name);
		return -EINVAL;
	}

	if (!device_is_ready(flt_int_dt.port)) {
		LOG_ERR("Can't get the device %s", flt_int_dt.port->name);
		return -EINVAL;
	}

	if (!device_is_ready(pulse1_out_dt.port)) {
		LOG_ERR("Can't get the device %s", pulse1_out_dt.port->name);
		return -EINVAL;
	}

	if (!device_is_ready(pwm1_out_dt.port)) {
		LOG_ERR("Can't get the device %s", pwm1_out_dt.port->name);
		return -EINVAL;
	}

	if (!device_is_ready(oc1_int_dt.port)) {
		LOG_ERR("Can't get the device %s", oc1_int_dt.port->name);
		return -EINVAL;
	}

	if (!device_is_ready(ov1_int_dt.port)) {
		LOG_ERR("Can't get the device %s", ov1_int_dt.port->name);
		return -EINVAL;
	}

    gpio_pin_configure_dt(&global_en_dt, GPIO_INPUT | GPIO_PULL_UP);
    gpio_pin_configure_dt(&status_out_dt, GPIO_OUTPUT);
    gpio_pin_configure_dt(&reset_int_dt, GPIO_INPUT);
    gpio_pin_configure_dt(&fan_out_dt, GPIO_OUTPUT);
    gpio_pin_configure_dt(&ot_int_dt, GPIO_INPUT);
    gpio_pin_configure_dt(&oc2_int_dt, GPIO_INPUT);
    gpio_pin_configure_dt(&ov2_int_dt, GPIO_INPUT);
    gpio_pin_configure_dt(&pulse2_out_dt, GPIO_OUTPUT);
    gpio_pin_configure_dt(&pwm2_out_dt, GPIO_OUTPUT);
    gpio_pin_configure_dt(&state2_out_dt, GPIO_OUTPUT);
    gpio_pin_configure_dt(&state3_out_dt, GPIO_OUTPUT);
    gpio_pin_configure_dt(&drv_en2_out_dt, GPIO_OUTPUT);
    gpio_pin_configure_dt(&drv_en1_out_dt, GPIO_OUTPUT);
    gpio_pin_configure_dt(&rs232_shdn_out_dt, GPIO_OUTPUT);
    gpio_pin_configure_dt(&rs232_en_out_dt, GPIO_OUTPUT);
    gpio_pin_configure_dt(&reset_n_out_dt, GPIO_OUTPUT);
    gpio_pin_configure_dt(&state1_out_dt, GPIO_OUTPUT);
    gpio_pin_configure_dt(&flt_int_dt, GPIO_INPUT);
    gpio_pin_configure_dt(&pulse1_out_dt, GPIO_OUTPUT);
    gpio_pin_configure_dt(&pwm1_out_dt, GPIO_OUTPUT);
    gpio_pin_configure_dt(&oc1_int_dt, GPIO_INPUT);
    gpio_pin_configure_dt(&ov1_int_dt, GPIO_INPUT);

    /* RS232 SHDN -> constant high by default */
    gpio_pin_set_dt(&rs232_shdn_out_dt, 1U);
    /* RS232 EN -> constant low by default */
    gpio_pin_set_dt(&rs232_en_out_dt, 0U);

    gpio_pin_interrupt_configure_dt(&global_en_dt, GPIO_INT_EDGE_BOTH);
	gpio_init_callback(&global_en_cb, global_en_callback_handler, BIT(global_en_dt.pin));
	gpio_add_callback(global_en_dt.port, &global_en_cb);

    gpio_pin_interrupt_configure_dt(&reset_int_dt, GPIO_INT_EDGE_RISING);
	gpio_init_callback(&reset_int_cb, reset_int_callback_handler, BIT(reset_int_dt.pin));
	gpio_add_callback(reset_int_dt.port, &reset_int_cb);

    gpio_pin_interrupt_configure_dt(&ot_int_dt, GPIO_INT_EDGE_RISING);
	gpio_init_callback(&ot_int_cb, ot_int_callback_handler, BIT(ot_int_dt.pin));
	gpio_add_callback(ot_int_dt.port, &ot_int_cb);

    gpio_pin_interrupt_configure_dt(&oc2_int_dt, GPIO_INT_EDGE_RISING);
	gpio_init_callback(&oc2_int_cb, oc2_int_callback_handler, BIT(oc2_int_dt.pin));
	gpio_add_callback(oc2_int_dt.port, &oc2_int_cb);

    gpio_pin_interrupt_configure_dt(&ov2_int_dt, GPIO_INT_EDGE_RISING);
	gpio_init_callback(&ov2_int_cb, ov2_int_callback_handler, BIT(ov2_int_dt.pin));
	gpio_add_callback(ov2_int_dt.port, &ov2_int_cb);

    gpio_pin_interrupt_configure_dt(&flt_int_dt, GPIO_INT_EDGE_RISING);
	gpio_init_callback(&flt_int_cb, flt_int_callback_handler, BIT(flt_int_dt.pin));
	gpio_add_callback(flt_int_dt.port, &flt_int_cb);

    gpio_pin_interrupt_configure_dt(&oc1_int_dt, GPIO_INT_EDGE_RISING);
	gpio_init_callback(&oc1_int_cb, oc1_int_callback_handler, BIT(oc1_int_dt.pin));
	gpio_add_callback(oc1_int_dt.port, &oc1_int_cb);

    gpio_pin_interrupt_configure_dt(&ov1_int_dt, GPIO_INT_EDGE_RISING);
	gpio_init_callback(&ov1_int_cb, ov1_int_callback_handler, BIT(ov1_int_dt.pin));
	gpio_add_callback(ov1_int_dt.port, &ov1_int_cb);

	LOG_DBG("Initialized the IO Interface successfully");
	return 0;
}

void io_set(int id, int level) {
	switch (id) {
	case IO_STATUS_OUT:
		gpio_pin_set_dt(&status_out_dt, level);
		break;
	case IO_FAN_OUT:
		gpio_pin_set_dt(&fan_out_dt, level);
		break;
	case IO_PULSE2_OUT:
		gpio_pin_set_dt(&pulse2_out_dt, level);
		break;
	case IO_PWM2_OUT:
		gpio_pin_set_dt(&pwm2_out_dt, level);
		break;
	case IO_STATE2_OUT:
		gpio_pin_set_dt(&state2_out_dt, level);
		break;
	case IO_STATE3_OUT:
		gpio_pin_set_dt(&state3_out_dt, level);
		break;
	case IO_DRV_EN2_OUT:
		gpio_pin_set_dt(&drv_en2_out_dt, level);
		break;
	case IO_DRV_EN1_OUT:
		gpio_pin_set_dt(&drv_en1_out_dt, level);
		break;
	case IO_RS232_SHDN_OUT:
		gpio_pin_set_dt(&rs232_shdn_out_dt, level);
		break;
	case IO_RESET_N_OUT:
		gpio_pin_set_dt(&reset_n_out_dt, level);
		break;
	case IO_RS232_EN_OUT:
		gpio_pin_set_dt(&rs232_en_out_dt, level);
		break;
	case IO_STATE1_OUT:
		gpio_pin_set_dt(&state1_out_dt, level);
		break;
	case IO_PULSE1_OUT:
		gpio_pin_set_dt(&pulse1_out_dt, level);
		break;
	case IO_PWM1_OUT:
		gpio_pin_set_dt(&pwm1_out_dt, level);
		break;
	default:
		break;
	}
}

int io_get(int id) {
	switch (id) {
		case IO_GLOBAL_EN:
			return gpio_pin_get_dt(&global_en_dt);
		case IO_STATUS_OUT:
			return gpio_pin_get_dt(&status_out_dt);
		case IO_RESET_INT:
			return gpio_pin_get_dt(&reset_int_dt);
		case IO_FAN_OUT:
			return gpio_pin_get_dt(&fan_out_dt);
		case IO_OT_INT:
			return gpio_pin_get_dt(&ot_int_dt);
		case IO_OC2_INT:
			return gpio_pin_get_dt(&oc2_int_dt);
		case IO_OV2_INT:
			return gpio_pin_get_dt(&ov2_int_dt);
		case IO_PULSE2_OUT:
			return gpio_pin_get_dt(&pulse2_out_dt);
		case IO_PWM2_OUT:
			return gpio_pin_get_dt(&pwm2_out_dt);
		case IO_STATE2_OUT:
			return gpio_pin_get_dt(&state2_out_dt);
		case IO_STATE3_OUT:
			return gpio_pin_get_dt(&state3_out_dt);
		case IO_DRV_EN2_OUT:
			return gpio_pin_get_dt(&drv_en2_out_dt);
		case IO_DRV_EN1_OUT:
			return gpio_pin_get_dt(&drv_en1_out_dt);
		case IO_RS232_SHDN_OUT:
			return gpio_pin_get_dt(&rs232_shdn_out_dt);
		case IO_RS232_EN_OUT:
			return gpio_pin_get_dt(&rs232_en_out_dt);
		case IO_RESET_N_OUT:
			return gpio_pin_get_dt(&reset_n_out_dt);
		case IO_STATE1_OUT:
			return gpio_pin_get_dt(&state1_out_dt);
		case IO_FLT_INT:
			return gpio_pin_get_dt(&flt_int_dt);
		case IO_PULSE1_OUT:
			return gpio_pin_get_dt(&pulse1_out_dt);
		case IO_PWM1_OUT:
			return gpio_pin_get_dt(&pwm1_out_dt);
		case IO_OC1_INT:
			return gpio_pin_get_dt(&oc1_int_dt);
		case IO_OV1_INT:
			return gpio_pin_get_dt(&ov1_int_dt);
	}
	return -EINVAL;
}

void io_interrupt_enable(void) {
    gpio_pin_interrupt_configure_dt(&reset_int_dt, GPIO_INT_EDGE_RISING);
	gpio_add_callback(reset_int_dt.port, &reset_int_cb);

    gpio_pin_interrupt_configure_dt(&ot_int_dt, GPIO_INT_EDGE_RISING);
	gpio_add_callback(ot_int_dt.port, &ot_int_cb);

    gpio_pin_interrupt_configure_dt(&oc2_int_dt, GPIO_INT_EDGE_RISING);
	gpio_add_callback(oc2_int_dt.port, &oc2_int_cb);

    gpio_pin_interrupt_configure_dt(&ov2_int_dt, GPIO_INT_EDGE_RISING);
	gpio_add_callback(ov2_int_dt.port, &ov2_int_cb);

    gpio_pin_interrupt_configure_dt(&flt_int_dt, GPIO_INT_EDGE_RISING);
	gpio_add_callback(flt_int_dt.port, &flt_int_cb);

    gpio_pin_interrupt_configure_dt(&oc1_int_dt, GPIO_INT_EDGE_RISING);
	gpio_add_callback(oc1_int_dt.port, &oc1_int_cb);

    gpio_pin_interrupt_configure_dt(&ov1_int_dt, GPIO_INT_EDGE_RISING);
	gpio_add_callback(ov1_int_dt.port, &ov1_int_cb);
}

void io_interrupt_disable(void) {
    gpio_pin_interrupt_configure_dt(&reset_int_dt, GPIO_INT_DISABLE);
	gpio_remove_callback(reset_int_dt.port, &reset_int_cb);

    gpio_pin_interrupt_configure_dt(&ot_int_dt, GPIO_INT_DISABLE);
	gpio_remove_callback(ot_int_dt.port, &ot_int_cb);

    gpio_pin_interrupt_configure_dt(&oc2_int_dt, GPIO_INT_DISABLE);
	gpio_remove_callback(oc2_int_dt.port, &oc2_int_cb);

    gpio_pin_interrupt_configure_dt(&ov2_int_dt, GPIO_INT_DISABLE);
	gpio_remove_callback(ov2_int_dt.port, &ov2_int_cb);

    gpio_pin_interrupt_configure_dt(&flt_int_dt, GPIO_INT_DISABLE);
	gpio_remove_callback(flt_int_dt.port, &flt_int_cb);

    gpio_pin_interrupt_configure_dt(&oc1_int_dt, GPIO_INT_DISABLE);
	gpio_remove_callback(oc1_int_dt.port, &oc1_int_cb);

    gpio_pin_interrupt_configure_dt(&ov1_int_dt, GPIO_INT_DISABLE);
	gpio_remove_callback(ov1_int_dt.port, &ov1_int_cb);
}
```

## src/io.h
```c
#ifndef IO_H_
#define IO_H_

#include <stdint.h>

enum {
    IO_GLOBAL_EN,
    IO_STATUS_OUT,
    IO_RESET_INT,
    IO_FAN_OUT,
    IO_OT_INT,
    IO_OC2_INT,
    IO_OV2_INT,
    IO_PULSE2_OUT,
    IO_PWM2_OUT,
    IO_STATE2_OUT,
    IO_STATE3_OUT,
    IO_DRV_EN2_OUT,
    IO_DRV_EN1_OUT,
    IO_RS232_SHDN_OUT,
    IO_RS232_EN_OUT,
    IO_RESET_N_OUT,
    IO_STATE1_OUT,
    IO_FLT_INT,
    IO_PULSE1_OUT,
    IO_PWM1_OUT,
    IO_OC1_INT,
    IO_OV1_INT,
};

int io_init(void);
void io_interrupt_enable(void);
void io_interrupt_disable(void);
void io_set(int id, int level);
int io_get(int id);

#endif /* IO_H_ */
```

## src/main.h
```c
#ifndef MAIN_H_
#define MAIN_H_

#include <stdint.h>

struct alma_data {
    uint32_t sync_freq;
    uint8_t jitter;
    uint32_t pulse_freq;
    uint8_t pulse_dc[2];
    uint8_t op_mode;
    uint8_t pulse_mode;
};

#endif /* MAIN_H_ */
```

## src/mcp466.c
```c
#include <zephyr/kernel.h>
#include <zephyr/drivers/i2c.h>

#include <zephyr/logging/log.h>
LOG_MODULE_REGISTER(mcp466_alma, LOG_LEVEL_DBG);

static const struct device *const mcp466_dev = DEVICE_DT_GET(DT_NODELABEL(i2c1));

void mcp466_init(void) {
    if (!device_is_ready(mcp466_dev)) {
		LOG_ERR("MCP466 device %s is not ready", mcp466_dev->name);
		return;
    }
}

void mcp466_write(int channel, uint8_t reg, uint16_t value) {
    if (!device_is_ready(mcp466_dev)) {
		LOG_ERR("MCP466 device %s is not ready", mcp466_dev->name);
		return;
    }

    uint8_t first_cmd_byte = 0x00;
    uint8_t second_cmd_byte = 0x00;
    uint16_t temp_data = value;
    uint8_t temp_byte = 0;
    // Prep the command bytes to write to the digital potentiometer
    reg *= 16;                // Shift the value of reg to the left by four bits
    first_cmd_byte |= reg;  // Load the register address into the first_cmd_byte
    temp_data &= 0x0100;            // Clear the top 7 bits and the lower byte of the input value to pick up the two data bits
    temp_data /= 256;               // Shift the top byte of the input value to the right by one byte
    temp_byte = (uint8_t)(temp_data);     // Store the top byte of the input value in a byte sized variable
    first_cmd_byte |= temp_byte;  // Load the two top input data bits into the first_cmd_byte
    temp_data = value;              // Load the input value into the temp_data
    temp_data &= 0x00FF;              // Clear the top byte
    second_cmd_byte = (uint8_t)(temp_data);  // Store the lower byte of the input value in the second_cmd_byte

    uint8_t tx_buf[2] = {first_cmd_byte, second_cmd_byte};
    i2c_write(mcp466_dev, tx_buf, sizeof(tx_buf), channel);
}

uint16_t mcp466_read(int channel, uint8_t reg) {
    if (!device_is_ready(mcp466_dev)) {
		LOG_ERR("MCP466 device %s is not ready", mcp466_dev->name);
		return 0;
    }

    uint8_t first_cmd_byte = 0x0C; // Prep the first_cmd_byte with 11b for reads
    // Prep the command bytes to read from the digital potentiometer
    reg *= 16; // Shift the value of Register to the left by four bits
    first_cmd_byte |= reg; // Load the register address into the first_cmd_byte

    uint8_t tx_buf[1] = {first_cmd_byte};
    uint8_t rx_buf[2] = {0x00};
    i2c_write_read(mcp466_dev, channel, tx_buf, sizeof(tx_buf), rx_buf, sizeof(rx_buf));

    return (uint16_t)(rx_buf[0] << 8 | rx_buf[1]);
}

void mcp466_up(int channel, uint8_t reg) {
    if (!device_is_ready(mcp466_dev)) {
		LOG_ERR("MCP466 device %s is not ready", mcp466_dev->name);
		return;
    }

    uint8_t first_cmd_byte = 0x04; // Prep the first_cmd_byte 01b to increment the reg 
    // Prep the command bytes to read from the digital potentiometer
    reg *= 16; // Shift the value of Register to the left by four bits
    first_cmd_byte |= reg; // Load the register address into the first_cmd_byte

    uint8_t tx_buf[1] = {first_cmd_byte};
    i2c_write(mcp466_dev, tx_buf, sizeof(tx_buf), channel);
}

void mcp466_down(int channel, uint8_t reg) {
    if (!device_is_ready(mcp466_dev)) {
		LOG_ERR("MCP466 device %s is not ready", mcp466_dev->name);
		return;
    }

    uint8_t first_cmd_byte = 0x08; // Prep the first_cmd_byte 0x08 to decrement  the reg 
    // Prep the command bytes to read from the digital potentiometer
    reg *= 16; // Shift the value of Register to the left by four bits
    first_cmd_byte |= reg; // Load the register address into the first_cmd_byte

    uint8_t tx_buf[1] = {first_cmd_byte};
    i2c_write(mcp466_dev, tx_buf, sizeof(tx_buf), channel);
}
```
